VERSION "1.0.0"

NS_ :

BS_:
BU_: DBG DUT

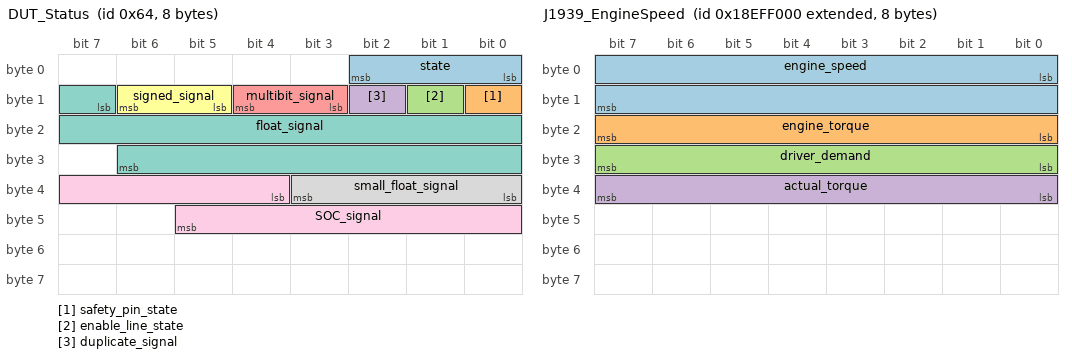
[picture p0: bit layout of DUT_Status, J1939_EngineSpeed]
BO_ 100 DUT_Status: 8 DUT
 SG_ state : 0|3@1+ (1,0) [0|0] "" DBG
 SG_ safety_pin_state : 8|1@1+ (1,0) [0|0] "" DBG
 SG_ enable_line_state : 9|1@1+ (1,0) [0|0] "" DBG
 SG_ duplicate_signal : 10|1@1+ (1,0) [0|0] "" DBG
 SG_ multibit_signal : 11|2@1+ (1,0) [0|0] "" DBG
 SG_ signed_signal : 13|2@1- (1,0) [0|0] "" DBG
 SG_ float_signal : 15|16@1+ (1,0) [0|0] "" DBG
 SG_ small_float_signal : 32|4@1+ (0.1,0) [0|0] "" DBG
 SG_ SOC_signal : 36|10@1+ (1.0977517,0) [0|100] "Percent" DBG

BO_ 200 DUT_Command: 1 DBG
 SG_ state_request : 0|3@1+ (1,0) [0|0] "" DUT,DBG

BO_ 300 DUT_Logging: 2 DUT
 SG_ logging_mux M : 0|4@1+ (1,0) [0|0] "" DBG
 SG_ logging_signal0 m0 : 4|1@1+ (1,0) [0|0] "" DBG
 SG_ logging_signal1 m1 : 4|1@1+ (1,0) [0|0] "" DBG
 SG_ logging_signal2 m2 : 4|1@1+ (1,0) [0|0] "" DBG
 SG_ no_mux_logging_signal : 5|1@1+ (1,0) [0|0] "" DBG

BO_ 400 Duplicate_Message: 1 DUT
 SG_ duplicate_signal : 0|1@1+ (1,0) [0|0] "" DBG

BO_ 500 Duplicate_Message: 1 DUT
 SG_ duplicate_signal : 0|1@1+ (1,0) [0|0] "" DBG

BO_ 600 Mixed_Message: 2 DUT
 SG_ muxer M : 0|4@1+ (1,0) [0|0] "" DBG
 SG_ muxed_signal m0 : 4|1@1+ (1,0) [0|0] "" DBG
 SG_ nonmuxed_signal : 5|1@1+ (1,0) [0|0] "" DBG

BO_ 700 Duplicate_Msg_Sig: 1 DUT
 SG_ Duplicate_Msg_Sig : 0|1@1+ (1,0) [0|0] "" DBG

BO_ 800 Signalless_Message: 1 DUT

BO_ 800 Signalless_Muxed_Message: 1 DUT
  SG_ muxer M : 0|4@1+ (1,0) [0|0] "" DBG

BO_ 2565861376 J1939_EngineSpeed: 8 DUT
 SG_ engine_speed : 0|16@1+ (0.125,0) [0|8031.875] "rpm" DBG
 SG_ engine_torque : 16|8@1+ (1,-125) [-125|125] "%" DBG
 SG_ driver_demand : 24|8@1+ (1,-125) [-125|125] "%" DBG
 SG_ actual_torque : 32|8@1+ (1,-125) [-125|125] "%" DBG

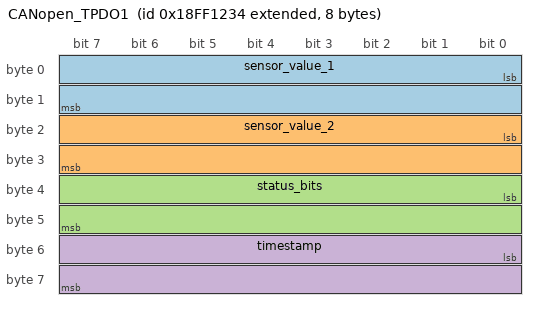
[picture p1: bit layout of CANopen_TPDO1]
BO_ 2566853172 CANopen_TPDO1: 8 DUT
 SG_ sensor_value_1 : 0|16@1+ (0.01,0) [0|655.35] "V" DBG
 SG_ sensor_value_2 : 16|16@1+ (0.01,0) [0|655.35] "A" DBG
 SG_ status_bits : 32|16@1+ (1,0) [0|0] "" DBG
 SG_ timestamp : 48|16@1+ (1,0) [0|65535] "ms" DBG

BO_ 2684354304 CANFD_BulkData: 64 DUT
 SG_ data_counter : 0|32@1+ (1,0) [0|0] "" DBG
 SG_ payload_byte_0 : 32|8@1+ (1,0) [0|255] "" DBG
 SG_ payload_byte_1 : 40|8@1+ (1,0) [0|255] "" DBG
 SG_ payload_byte_2 : 48|8@1+ (1,0) [0|255] "" DBG
 SG_ checksum : 504|8@1+ (1,0) [0|255] "" DBG

BO_ 2684354528 CANFD_HighSpeed: 32 DUT
 SG_ sequence_number : 0|16@1+ (1,0) [0|65535] "" DBG
 SG_ temperature_1 : 16|16@1- (0.1,-40) [-40|100] "degC" DBG
 SG_ temperature_2 : 32|16@1- (0.1,-40) [-40|100] "degC" DBG
 SG_ pressure_1 : 48|16@1+ (0.01,0) [0|655.35] "bar" DBG
 SG_ pressure_2 : 64|16@1+ (0.01,0) [0|655.35] "bar" DBG
 SG_ status_flags : 80|32@1+ (1,0) [0|0] "" DBG

CM_ BU_ DBG "The ZUBoard DBG/Controller Node";
CM_ BU_ DUT "The device under test node (ex: STM32)";

CM_ BO_ 100 "Message used to describe the DUTs status";
CM_ BO_ 200 "Message used to describe the DUTs commands";
CM_ BO_ 300 "Logging message";
CM_ BO_ 2565861376 "J1939 Engine Speed and Torque (29-bit Extended ID 0x18EFF000)";
CM_ BO_ 2566853172 "CANopen TPDO1 - Process Data Object (29-bit Extended ID 0x18FF1234)";
CM_ BO_ 2684354304 "CAN-FD Bulk Data Transfer (64 bytes, 29-bit Extended ID 0x1FFFFF00)";
CM_ BO_ 2684354528 "CAN-FD High-Speed Sensor Data (32 bytes, 29-bit Extended ID 0x1FFFFFE0)";

BA_DEF_ "BusType" STRING ;
BA_DEF_ SG_ "FieldType" STRING ;
BA_DEF_ BO_ "GenMsgCycleTime" INT 0 0;

BA_DEF_DEF_ "BusType" "CAN";
BA_DEF_DEF_ "FieldType" "";
BA_DEF_DEF_ "GenMsgCycleTime" 0;

BA_ "GenMsgCycleTime" BO_ 100 1000;
BA_ "GenMsgCycleTime" BO_ 200 100;
BA_ "GenMsgCycleTime" BO_ 300 100;
BA_ "GenMsgCycleTime" BO_ 400 100;
BA_ "GenMsgCycleTime" BO_ 500 100;
BA_ "GenMsgCycleTime" BO_ 2565861376 50;
BA_ "GenMsgCycleTime" BO_ 2566853172 100;
BA_ "GenMsgCycleTime" BO_ 2684354304 200;
BA_ "GenMsgCycleTime" BO_ 2684354528 20;

BA_ "FieldType" SG_ 100 state "state";
BA_ "FieldType" SG_ 200 state_request "state_request";

VAL_ 100 state 2 "DUT_STATE_FAULTED" 1 "DUT_STATE_ACTIVE" 0 "DUT_STATE_STANDBY" ;
VAL_ 200 state_request 1 "STATE_REQUEST_ACTIVE" 0 "STATE_REQUEST_STANDBY";

SIG_VALTYPE_ 100 float_signal : 1;
VAL_ 300 logging_mux 0 "LOGGING_MUX_ZERO" 1 "LOGGING_MUX_ONE" ;

VAL_ 800 muxer 0 "MUX_ZERO" 1 "MUX_ONE" ;
